AUTOSAR XML (schema 4-3-0)
package /ComponentTypes
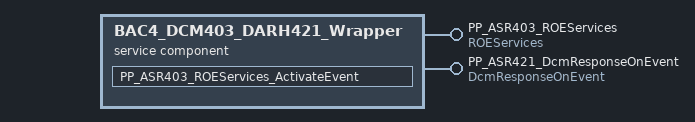
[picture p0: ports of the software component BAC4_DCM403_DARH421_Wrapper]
  service sw component type BAC4_DCM403_DARH421_Wrapper  # Converts the the DCM ASR4.0.3 CS interface into ASR4.2.1 intface needed by DARH
    provide port PP_ASR403_ROEServices: server-com-spec{operation=ActivateEvent, queue-length=1}, provided-interface=ROEServices
    provide port PP_ASR421_DcmResponseOnEvent: mode-switch-sender-com-spec{enhanced-mode-api=false, mode-group=currentMode, queue-length=1}, provided-interface=DcmResponseOnEvent
    behavior BAC4_DCM403_DARH421_Wrapper_InternalBehavior
      operation invoked event OIT_PP_ASR403_ROEServices_ActivateEvent_PP_ASR403_ROEServices_ActivateEvent: start-on-event=PP_ASR403_ROEServices_ActivateEvent, operation=PP_ASR403_ROEServices.ActivateEvent
      runnable PP_ASR403_ROEServices_ActivateEvent: mode-access-point=PP_ASR421_DcmResponseOnEvent.currentMode
        mode switch point SWITCH_PP_ASR421_DcmResponseOnEvent_currentMode: mode-group=PP_ASR421_DcmResponseOnEvent.currentMode
  swc implementation BAC4_DCM403_DARH421_Wrapper_Implementation: behavior=BAC4_DCM403_DARH421_Wrapper_InternalBehavior
    code-descriptors:
      code Default: artifact-descriptors=autosar-engineering-object={short-label=Default, category=SWSRC}
